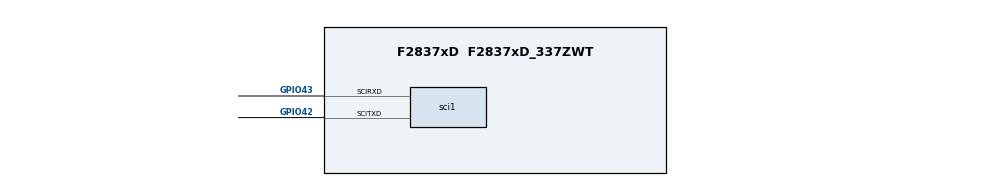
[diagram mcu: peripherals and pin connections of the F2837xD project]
/**
 * @cliArgs --board "/boards/LAUNCHXL_F28379D" --device "F2837xD" --part "F2837xD_337ZWT" --package "F2837xD_337ZWT" --context "CPU1" --product "C2000WARE@26.00.00.00"
 * @versions {"tool":"1.27.0+4565"}
 */

/**
 * Import the modules used in this configuration.
 */
const cla       = scripting.addModule("/driverlib/cla.js", {}, false);
const cla1      = cla.addInstance();
const cputimer  = scripting.addModule("/driverlib/cputimer.js", {}, false);
const cputimer1 = cputimer.addInstance();
const memcfg    = scripting.addModule("/driverlib/memcfg.js");
const sci       = scripting.addModule("/driverlib/sci.js", {}, false);
const sci1      = sci.addInstance();
const CMD       = scripting.addModule("/utilities/cmd_tool/cmd_syscfg/source/CMD", {}, false);
const CMD1      = CMD.addInstance();

/**
 * Write custom configuration values to the imported modules.
 */
cla1.$name             = "myCLA0";
cla1.enable_CLA_TASK_2 = false;
cla1.enable_CLA_TASK_4 = false;
cla1.enable_CLA_TASK_3 = false;
cla1.enable_CLA_TASK_5 = false;
cla1.enable_CLA_TASK_6 = false;
cla1.enable_CLA_TASK_7 = false;
cla1.enable_CLA_TASK_8 = false;
cla1.cpuint_CLA_TASK_2 = false;
cla1.cpuint_CLA_TASK_3 = false;
cla1.cpuint_CLA_TASK_5 = false;
cla1.cpuint_CLA_TASK_6 = false;
cla1.cpuint_CLA_TASK_7 = false;
cla1.cpuint_CLA_TASK_8 = false;
cla1.cpuint_CLA_TASK_4 = false;

cputimer1.$name                    = "myCPUTIMER0";
cputimer1.timerPeriod              = 9999;
cputimer1.enableInterrupt          = true;
cputimer1.startTimer               = true;
cputimer1.registerInterrupts       = true;
cputimer1.timerInt.enableInterrupt = true;

memcfg.init_MEMCFG_SECT_MSGCPUTOCLA1 = true;
memcfg.init_MEMCFG_SECT_MSGCLA1TOCPU = true;
memcfg.config_MEMCFG_SECT_LS1        = "CLA_data";
memcfg.config_MEMCFG_SECT_LS4        = "CLA_prog";
memcfg.config_MEMCFG_SECT_LS5        = "CLA_prog";

sci1.$name                      = "SCI0";
sci1.selectRegisteredInterrupts = ["registerRxInt"];
sci1.enabledFIFOInterrupts      = ["SCI_INT_RXFF"];
sci1.rxFifo                     = "SCI_FIFO_RX4";
sci1.sci.scirxdPin.$assign      = "GPIO43";
sci1.sci.scitxdPin.$assign      = "GPIO42";
sci1.rxQual.$name               = "myGPIOQUAL0";
sci1.txQual.$name               = "myGPIOQUAL1";
sci1.sciRXInt.enableInterrupt   = true;

CMD1.$name                         = "CMD0";
CMD1.sectionMemory_cla1ToCpuMsgRAM = ["CLATOCPU_MSGRAM"];
CMD1.sectionMemory_cpuToCla1MsgRAM = ["CPUTOCLA_MSGRAM"];
CMD1.sectionMemory_cla1Prog        = ["RAMLS5"];
CMD1.sectionMemory_claConst        = ["RAMLS1"];
CMD1.sectionMemory_claScratchpad   = ["RAMLS1"];

/**
 * Pinmux solution for unlocked pins/peripherals. This ensures that minor changes to the automatic solver in a future
 * version of the tool will not impact the pinmux you originally saw.  These lines can be completely deleted in order to
 * re-solve from scratch.
 */
sci1.sci.$suggestSolution = "SCIA";
